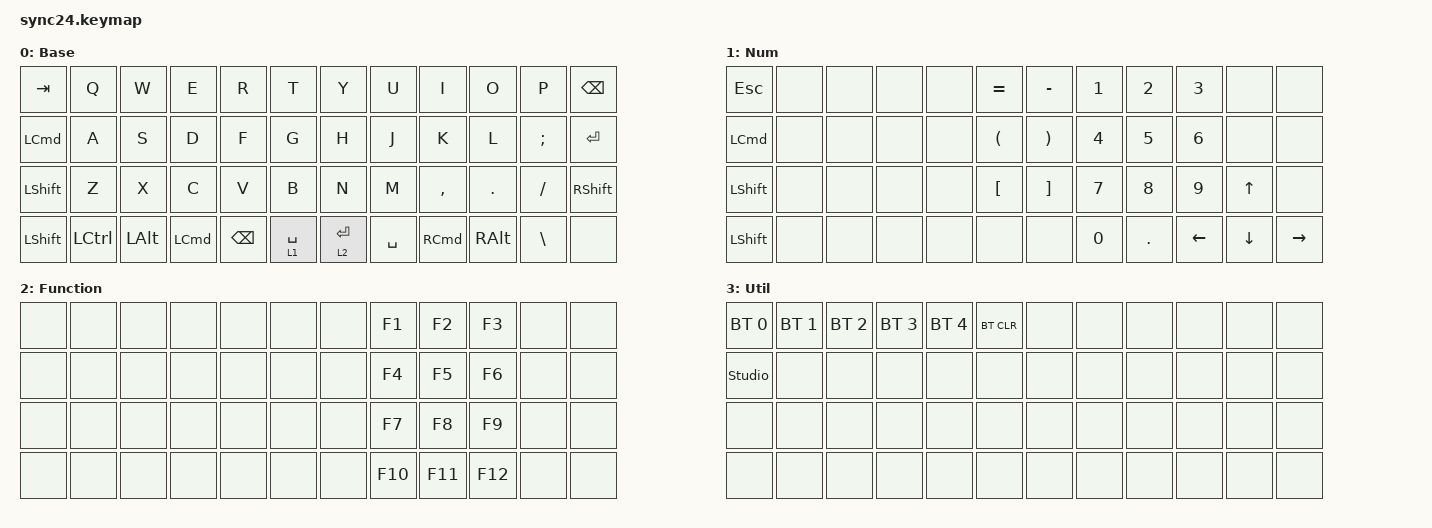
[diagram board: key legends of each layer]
#define ZMK_BEHAVIORS_OMIT_KT
#undef ZMK_BEHAVIORS_KEEP_ALL
#define ZMK_BEHAVIORS_KEEP_SK
#define ZMK_BEHAVIORS_KEEP_MT
#define ZMK_BEHAVIORS_KEEP_KT

#include <behaviors.dtsi>
#include <dt-bindings/zmk/keys.h>
#include <dt-bindings/zmk/bt.h>
#include <dt-bindings/zmk/outputs.h>

/ {
    /* ==========================================================================
       Macros: 同時押しされた際に出力される順序（子音→母音）を定義
       ========================================================================== */
    macros {
        // N系列
        m_na: m_na { compatible = "zmk,behavior-macro"; #binding-cells = <0>; bindings = <&kp N>, <&kp A>; };
        m_ni: m_ni { compatible = "zmk,behavior-macro"; #binding-cells = <0>; bindings = <&kp N>, <&kp I>; };
        m_nu: m_nu { compatible = "zmk,behavior-macro"; #binding-cells = <0>; bindings = <&kp N>, <&kp U>; };
        m_ne: m_ne { compatible = "zmk,behavior-macro"; #binding-cells = <0>; bindings = <&kp N>, <&kp E>; };
        m_no: m_no { compatible = "zmk,behavior-macro"; #binding-cells = <0>; bindings = <&kp N>, <&kp O>; };
        // K系列
        m_ka: m_ka { compatible = "zmk,behavior-macro"; #binding-cells = <0>; bindings = <&kp K>, <&kp A>; };
        m_ki: m_ki { compatible = "zmk,behavior-macro"; #binding-cells = <0>; bindings = <&kp K>, <&kp I>; };
        m_ku: m_ku { compatible = "zmk,behavior-macro"; #binding-cells = <0>; bindings = <&kp K>, <&kp U>; };
        m_ke: m_ke { compatible = "zmk,behavior-macro"; #binding-cells = <0>; bindings = <&kp K>, <&kp E>; };
        m_ko: m_ko { compatible = "zmk,behavior-macro"; #binding-cells = <0>; bindings = <&kp K>, <&kp O>; };
        // S系列
        m_sa: m_sa { compatible = "zmk,behavior-macro"; #binding-cells = <0>; bindings = <&kp S>, <&kp A>; };
        m_si: m_si { compatible = "zmk,behavior-macro"; #binding-cells = <0>; bindings = <&kp S>, <&kp I>; };
        m_su: m_su { compatible = "zmk,behavior-macro"; #binding-cells = <0>; bindings = <&kp S>, <&kp U>; };
        m_se: m_se { compatible = "zmk,behavior-macro"; #binding-cells = <0>; bindings = <&kp S>, <&kp E>; };
        m_so: m_so { compatible = "zmk,behavior-macro"; #binding-cells = <0>; bindings = <&kp S>, <&kp O>; };
        // T系列
        m_ta: m_ta { compatible = "zmk,behavior-macro"; #binding-cells = <0>; bindings = <&kp T>, <&kp A>; };
        m_ti: m_ti { compatible = "zmk,behavior-macro"; #binding-cells = <0>; bindings = <&kp T>, <&kp I>; };
        m_tu: m_tu { compatible = "zmk,behavior-macro"; #binding-cells = <0>; bindings = <&kp T>, <&kp U>; };
        m_te: m_te { compatible = "zmk,behavior-macro"; #binding-cells = <0>; bindings = <&kp T>, <&kp E>; };
        m_to: m_to { compatible = "zmk,behavior-macro"; #binding-cells = <0>; bindings = <&kp T>, <&kp O>; };
    }

    combos {
        compatible = "zmk,combos";

        /* --- 既存のCombo設定 --- */
        combo_us { timeout-ms = <50>; key-positions = <14 15>; bindings = <&kp LANG2>; };
        combo_kana { timeout-ms = <50>; key-positions = <20 21>; bindings = <&kp LANG1>; };
        combo_util { timeout-ms = <50>; key-positions = <36 37>; bindings = <&mo 3>; };

        /* --- 大西配列サポート用同時押し設定 (Timeout: 40ms) --- */
        // N(30) + 母音
        cb_na { timeout-ms = <40>; key-positions = <30 13>; bindings = <&m_na>; }; // A=13
        cb_ni { timeout-ms = <40>; key-positions = <30 8>;  bindings = <&m_ni>; }; // I=8
        cb_nu { timeout-ms = <40>; key-positions = <30 7>;  bindings = <&m_nu>; }; // U=7
        cb_ne { timeout-ms = <40>; key-positions = <30 3>;  bindings = <&m_ne>; }; // E=3
        cb_no { timeout-ms = <40>; key-positions = <30 9>;  bindings = <&m_no>; }; // O=9

        // K(20) + 母音
        cb_ka { timeout-ms = <40>; key-positions = <20 13>; bindings = <&m_ka>; };
        cb_ki { timeout-ms = <40>; key-positions = <20 8>;  bindings = <&m_ki>; };
        cb_ku { timeout-ms = <40>; key-positions = <20 7>;  bindings = <&m_ku>; };
        cb_ke { timeout-ms = <40>; key-positions = <20 3>;  bindings = <&m_ke>; };
        cb_ko { timeout-ms = <40>; key-positions = <20 9>;  bindings = <&m_ko>; };

        // S(14) + 母音
        cb_sa { timeout-ms = <40>; key-positions = <14 13>; bindings = <&m_sa>; };
        cb_si { timeout-ms = <40>; key-positions = <14 8>;  bindings = <&m_si>; };
        cb_su { timeout-ms = <40>; key-positions = <14 7>;  bindings = <&m_su>; };
        cb_se { timeout-ms = <40>; key-positions = <14 3>;  bindings = <&m_se>; };
        cb_so { timeout-ms = <40>; key-positions = <14 9>;  bindings = <&m_so>; };

        // T(5) + 母音
        cb_ta { timeout-ms = <40>; key-positions = <5 13>; bindings = <&m_ta>; };
        cb_ti { timeout-ms = <40>; key-positions = <5 8>;  bindings = <&m_ti>; };
        cb_tu { timeout-ms = <40>; key-positions = <5 7>;  bindings = <&m_tu>; };
        cb_te { timeout-ms = <40>; key-positions = <5 3>;  bindings = <&m_te>; };
        cb_to { timeout-ms = <40>; key-positions = <5 9>;  bindings = <&m_to>; };
    };

    keymap {
        compatible = "zmk,keymap";
        base {
            display-name = "Base";
            bindings = <
    &kp TAB    &kp Q       &kp W       &kp E       &kp R       &kp T            &kp Y       &kp U       &kp I       &kp O       &kp P         &kp BACKSPACE 
    &kp LCMD   &kp A       &kp S       &kp D       &kp F       &kp G            &kp H       &kp J       &kp K       &kp L       &kp SEMICOLON &kp RET
    &kp LSHFT  &kp Z       &kp X       &kp C       &kp V       &kp B            &kp N       &kp M       &kp COMMA   &kp DOT     &kp FSLH      &kp RSHIFT
    &kp LSHFT  &kp LCTRL   &kp LALT    &kp LCMD    &kp BSPC    &lt 1 SPACE      &lt 2 RET   &kp SPACE   &kp RCMD    &kp RALT    &kp BSLH      &none
            >;
        };

        num {
            display-name = "Num";
            bindings = <
    &kp ESC     &none       &none       &none       &none       &kp EQUAL       &kp MINUS   &kp N1      &kp N2      &kp N3         &none          &none
    &kp LCMD    &none       &none       &none       &none       &kp LPAR        &kp RPAR    &kp N4      &kp N5      &kp N6         &none          &none
    &kp LSHFT   &none       &none       &none       &none       &kp LBKT        &kp RBKT    &kp N7      &kp N8      &kp N9         &kp UP_ARROW   &none
    &kp LSHFT   &none       &none       &none       &none       &none           &none       &kp N0      &kp DOT     &kp LEFT_ARROW &kp DOWN_ARROW &kp RIGHT_ARROW
            >;
        };

        function {
            display-name = "Function";
            bindings = <
    &none       &none       &none       &none       &none       &none           &none       &kp F1      &kp F2      &kp F3      &none       &none
    &none       &none       &none       &none       &none       &none           &none       &kp F4      &kp F5      &kp F6      &none       &none
    &none       &none       &none       &none       &none       &none           &none       &kp F7      &kp F8      &kp F9      &none       &none
    &none       &none       &none       &none       &none       &none           &none       &kp F10     &kp F11     &kp F12     &none       &none
            >;
        };

        util {
            display-name = "Util";
            bindings = <
    &bt BT_SEL 0    &bt BT_SEL 1&bt BT_SEL 2&bt BT_SEL 3&bt BT_SEL 4&bt BT_CLR      &none       &none       &none       &none       &none       &none
    &studio_unlock  &none       &none       &none       &none       &none           &none       &none       &none       &none       &none       &none
    &none           &none       &none       &none       &none       &none           &none       &none       &none       &none       &none       &none
    &none           &none       &none       &none       &none       &none           &none       &none       &none       &none       &none       &none
            >;
        };
    };
};
